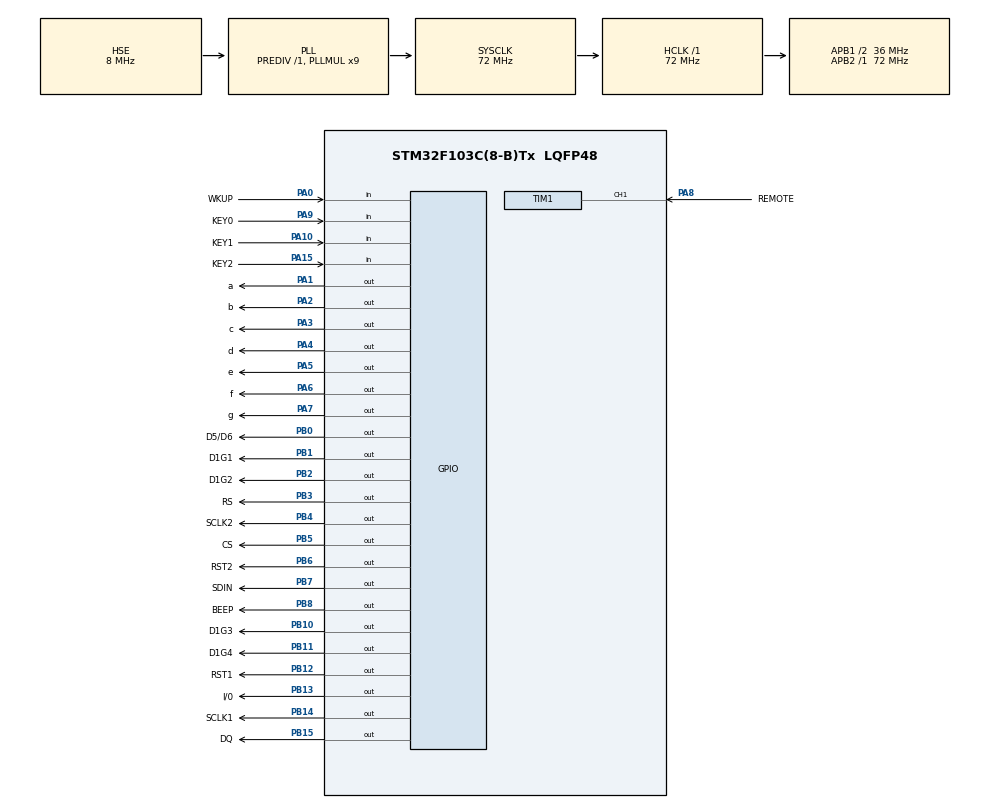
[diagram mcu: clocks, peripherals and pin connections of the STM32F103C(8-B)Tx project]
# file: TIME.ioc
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Mcu.Family=STM32F1
Mcu.Name=STM32F103C(8-B)Tx
Mcu.Package=LQFP48
NVIC.PriorityGroup=NVIC_PRIORITYGROUP_2
NVIC.TIM1_CC_IRQn=true\:1\:3\:true\:false\:true
NVIC.TIM1_UP_IRQn=true\:1\:2\:true\:false\:true
NVIC.TIM3_IRQn=true\:1\:3\:true\:false\:true
PA0-WKUP.GPIO_Label=WKUP
PA0-WKUP.GPIO_PuPd=GPIO_PULLDOWN
PA0-WKUP.Signal=GPIO_Input
PA1.GPIO_Label=a
PA1.GPIO_Speed=GPIO_SPEED_FREQ_HIGH
PA1.PinState=GPIO_PIN_RESET
PA1.Signal=GPIO_Output
PA10.GPIO_Label=KEY1
PA10.GPIO_PuPd=GPIO_PULLUP
PA10.Signal=GPIO_Input
PA13.Mode=Serial_Wire
PA13.Signal=SYS_JTMS-SWDIO
PA14.Mode=Serial_Wire
PA14.Signal=SYS_JTCK-SWCLK
PA15.GPIO_Label=KEY2
PA15.GPIO_PuPd=GPIO_PULLUP
PA15.Signal=GPIO_Input
PA2.GPIO_Label=b
PA2.GPIO_Speed=GPIO_SPEED_FREQ_HIGH
PA2.PinState=GPIO_PIN_RESET
PA2.Signal=GPIO_Output
PA3.GPIO_Label=c
PA3.GPIO_Speed=GPIO_SPEED_FREQ_HIGH
PA3.Signal=GPIO_Output
PA4.GPIO_Label=d
PA4.GPIO_Speed=GPIO_SPEED_FREQ_HIGH
PA4.Signal=GPIO_Output
PA5.GPIO_Label=e
PA5.GPIO_Speed=GPIO_SPEED_FREQ_HIGH
PA5.Signal=GPIO_Output
PA6.GPIO_Label=f
PA6.GPIO_Speed=GPIO_SPEED_FREQ_HIGH
PA6.Signal=GPIO_Output
PA7.GPIO_Label=g
PA7.GPIO_Speed=GPIO_SPEED_FREQ_HIGH
PA7.Signal=GPIO_Output
PA8.GPIO_Label=REMOTE
PA8.GPIO_PuPd=GPIO_PULLUP
PA8.Signal=S_TIM1_CH1
PA9.GPIO_Label=KEY0
PA9.GPIO_PuPd=GPIO_PULLUP
PA9.Signal=GPIO_Input
PB0.GPIO_Label=D5/D6
PB0.GPIO_Speed=GPIO_SPEED_FREQ_HIGH
PB0.Signal=GPIO_Output
PB1.GPIO_Label=D1G1
PB1.GPIO_Speed=GPIO_SPEED_FREQ_HIGH
PB1.Signal=GPIO_Output
PB10.GPIO_Label=D1G3
PB10.GPIO_Speed=GPIO_SPEED_FREQ_HIGH
PB10.Signal=GPIO_Output
PB11.GPIO_Label=D1G4
PB11.GPIO_Speed=GPIO_SPEED_FREQ_HIGH
PB11.Signal=GPIO_Output
PB12.GPIO_Label=RST1
PB12.GPIO_Speed=GPIO_SPEED_FREQ_HIGH
PB12.Signal=GPIO_Output
PB13.GPIO_Label=I/0
PB13.GPIO_Speed=GPIO_SPEED_FREQ_HIGH
PB13.Signal=GPIO_Output
PB14.GPIO_Label=SCLK1
PB14.GPIO_Speed=GPIO_SPEED_FREQ_HIGH
PB14.Signal=GPIO_Output
PB15.GPIO_Label=DQ
PB15.GPIO_Speed=GPIO_SPEED_FREQ_HIGH
PB15.Signal=GPIO_Output
PB2.GPIO_Label=D1G2
PB2.GPIO_Speed=GPIO_SPEED_FREQ_HIGH
PB2.Signal=GPIO_Output
PB3.GPIO_Label=RS
PB3.GPIO_Speed=GPIO_SPEED_FREQ_HIGH
PB3.Signal=GPIO_Output
PB4.GPIO_Label=SCLK2
PB4.GPIO_Speed=GPIO_SPEED_FREQ_HIGH
PB4.Signal=GPIO_Output
PB5.GPIO_Label=CS
PB5.GPIO_Speed=GPIO_SPEED_FREQ_HIGH
PB5.Signal=GPIO_Output
PB6.GPIO_Label=RST2
PB6.GPIO_Speed=GPIO_SPEED_FREQ_HIGH
PB6.Signal=GPIO_Output
PB7.GPIO_Label=SDIN
PB7.GPIO_Speed=GPIO_SPEED_FREQ_HIGH
PB7.Signal=GPIO_Output
PB8.GPIO_Label=BEEP
PB8.GPIO_Speed=GPIO_SPEED_FREQ_HIGH
PB8.PinState=GPIO_PIN_RESET
PB8.Signal=GPIO_Output
PD0-OSC_IN.Mode=HSE-External-Oscillator
PD0-OSC_IN.Signal=RCC_OSC_IN
PD1-OSC_OUT.Mode=HSE-External-Oscillator
PD1-OSC_OUT.Signal=RCC_OSC_OUT
ProjectManager.HeapSize=0x200
ProjectManager.StackSize=0x400
ProjectManager.TargetToolchain=MDK-ARM V5
RCC.AHBFreq_Value=72000000
RCC.APB1CLKDivider=RCC_HCLK_DIV2
RCC.APB1Freq_Value=36000000
RCC.APB1TimFreq_Value=72000000
RCC.APB2Freq_Value=72000000
RCC.APB2TimFreq_Value=72000000
RCC.HCLKFreq_Value=72000000
RCC.PLLMUL=RCC_PLL_MUL9
RCC.PLLSourceVirtual=RCC_PLLSOURCE_HSE
RCC.SYSCLKFreq_VALUE=72000000
RCC.SYSCLKSource=RCC_SYSCLKSOURCE_PLLCLK
RCC.USBFreq_Value=72000000
SH.S_TIM1_CH1.0=TIM1_CH1,Input_Capture1_from_TI1
TIM1.Channel-Input_Capture1_from_TI1=TIM_CHANNEL_1
TIM1.ICFilter_CH1=0x03
TIM1.Period=10000
TIM1.Prescaler=71
TIM3.Period=999
TIM3.Prescaler=71
VP_TIM1_VS_ClockSourceINT.Mode=Internal
VP_TIM3_VS_ClockSourceINT.Mode=Internal
board=TIME

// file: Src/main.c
/**
  ******************************************************************************
  * File Name          : main.c
  * Description        : Main program body
  ******************************************************************************
  ** This notice applies to any and all portions of this file
  * that are not between comment pairs USER CODE BEGIN and
  * USER CODE END. Other portions of this file, whether
  * inserted by the user or by software development tools
  * are owned by their respective copyright owners.
  *
  * COPYRIGHT(c) 2017 STMicroelectronics
  *
  * Redistribution and use in source and binary forms, with or without modification,
  * are permitted provided that the following conditions are met:
  *   1. Redistributions of source code must retain the above copyright notice,
  *      this list of conditions and the following disclaimer.
  *   2. Redistributions in binary form must reproduce the above copyright notice,
  *      this list of conditions and the following disclaimer in the documentation
  *      and/or other materials provided with the distribution.
  *   3. Neither the name of STMicroelectronics nor the names of its contributors
  *      may be used to endorse or promote products derived from this software
  *      without specific prior written permission.
  *
  * THIS SOFTWARE IS PROVIDED BY THE COPYRIGHT HOLDERS AND CONTRIBUTORS "AS IS"
  * AND ANY EXPRESS OR IMPLIED WARRANTIES, INCLUDING, BUT NOT LIMITED TO, THE
  * IMPLIED WARRANTIES OF MERCHANTABILITY AND FITNESS FOR A PARTICULAR PURPOSE ARE
  * DISCLAIMED. IN NO EVENT SHALL THE COPYRIGHT HOLDER OR CONTRIBUTORS BE LIABLE
  * FOR ANY DIRECT, INDIRECT, INCIDENTAL, SPECIAL, EXEMPLARY, OR CONSEQUENTIAL
  * DAMAGES (INCLUDING, BUT NOT LIMITED TO, PROCUREMENT OF SUBSTITUTE GOODS OR
  * SERVICES; LOSS OF USE, DATA, OR PROFITS; OR BUSINESS INTERRUPTION) HOWEVER
  * CAUSED AND ON ANY THEORY OF LIABILITY, WHETHER IN CONTRACT, STRICT LIABILITY,
  * OR TORT (INCLUDING NEGLIGENCE OR OTHERWISE) ARISING IN ANY WAY OUT OF THE USE
  * OF THIS SOFTWARE, EVEN IF ADVISED OF THE POSSIBILITY OF SUCH DAMAGE.
  *
  ******************************************************************************
  */
#include "main.h"
#include "stm32f1xx_hal.h"

/* USER CODE BEGIN Includes */
#include "oled.h"
#include "clock.h"
#include "ds1302.h"
#include "ds18b20.h"

/* USER CODE END Includes */

TIM_HandleTypeDef htim1;
TIM_HandleTypeDef htim3;

/* USER CODE BEGIN PV */
/* Private variables ---------------------------------------------------------*/

/* USER CODE END PV */

void SystemClock_Config(void);
static void MX_GPIO_Init(void);
static void MX_TIM1_Init(void);
static void MX_TIM3_Init(void);

/* USER CODE BEGIN PFP */
/* Private function prototypes -----------------------------------------------*/

/* USER CODE END PFP */

int main(void)
{

  /* MCU Configuration----------------------------------------------------------*/

  /* Reset of all peripherals, Initializes the Flash interface and the Systick. */
  HAL_Init();

  /* Configure the system clock */
  SystemClock_Config();

  /* Initialize all configured peripherals */
  MX_GPIO_Init();
  MX_TIM1_Init();
  MX_TIM3_Init();

  /* USER CODE BEGIN 2 */
	OLED_Init();
	OLED_Clear();
	DS1302_Init();
	DS18B20_Init();
  HAL_TIM_Base_Start_IT(&htim3);
	HAL_TIM_Base_Start_IT(&htim1);
	HAL_TIM_IC_Start_IT(&htim1,TIM_CHANNEL_1);
  /* USER CODE END 2 */

  /* Infinite loop */
  while (1)
  {

  /* USER CODE BEGIN 3 */
    clock();
  }
  /* USER CODE END 3 */

}

/** System Clock Configuration
*/
void SystemClock_Config(void)
{

  RCC_OscInitTypeDef RCC_OscInitStruct;
  RCC_ClkInitTypeDef RCC_ClkInitStruct;

    /**Initializes the CPU, AHB and APB busses clocks
    */
  RCC_OscInitStruct.OscillatorType = RCC_OSCILLATORTYPE_HSE;
  RCC_OscInitStruct.HSEState = RCC_HSE_ON;
  RCC_OscInitStruct.HSEPredivValue = RCC_HSE_PREDIV_DIV1;
  RCC_OscInitStruct.HSIState = RCC_HSI_ON;
  RCC_OscInitStruct.PLL.PLLState = RCC_PLL_ON;
  RCC_OscInitStruct.PLL.PLLSource = RCC_PLLSOURCE_HSE;
  RCC_OscInitStruct.PLL.PLLMUL = RCC_PLL_MUL9;
  if (HAL_RCC_OscConfig(&RCC_OscInitStruct) != HAL_OK)
  {
    _Error_Handler(__FILE__, __LINE__);
  }

    /**Initializes the CPU, AHB and APB busses clocks
    */
  RCC_ClkInitStruct.ClockType = RCC_CLOCKTYPE_HCLK|RCC_CLOCKTYPE_SYSCLK
                              |RCC_CLOCKTYPE_PCLK1|RCC_CLOCKTYPE_PCLK2;
  RCC_ClkInitStruct.SYSCLKSource = RCC_SYSCLKSOURCE_PLLCLK;
  RCC_ClkInitStruct.AHBCLKDivider = RCC_SYSCLK_DIV1;
  RCC_ClkInitStruct.APB1CLKDivider = RCC_HCLK_DIV2;
  RCC_ClkInitStruct.APB2CLKDivider = RCC_HCLK_DIV1;

  if (HAL_RCC_ClockConfig(&RCC_ClkInitStruct, FLASH_LATENCY_2) != HAL_OK)
  {
    _Error_Handler(__FILE__, __LINE__);
  }

    /**Configure the Systick interrupt time
    */
  HAL_SYSTICK_Config(HAL_RCC_GetHCLKFreq()/1000);

    /**Configure the Systick
    */
  HAL_SYSTICK_CLKSourceConfig(SYSTICK_CLKSOURCE_HCLK);

  /* SysTick_IRQn interrupt configuration */
  HAL_NVIC_SetPriority(SysTick_IRQn, 0, 0);
}

/* TIM1 init function */
static void MX_TIM1_Init(void)
{

  TIM_ClockConfigTypeDef sClockSourceConfig;
  TIM_MasterConfigTypeDef sMasterConfig;
  TIM_IC_InitTypeDef sConfigIC;

  htim1.Instance = TIM1;
  htim1.Init.Prescaler = 71;
  htim1.Init.CounterMode = TIM_COUNTERMODE_UP;
  htim1.Init.Period = 10000;
  htim1.Init.ClockDivision = TIM_CLOCKDIVISION_DIV1;
  htim1.Init.RepetitionCounter = 0;
  htim1.Init.AutoReloadPreload = TIM_AUTORELOAD_PRELOAD_DISABLE;
  if (HAL_TIM_Base_Init(&htim1) != HAL_OK)
  {
    _Error_Handler(__FILE__, __LINE__);
  }

  sClockSourceConfig.ClockSource = TIM_CLOCKSOURCE_INTERNAL;
  if (HAL_TIM_ConfigClockSource(&htim1, &sClockSourceConfig) != HAL_OK)
  {
    _Error_Handler(__FILE__, __LINE__);
  }

  if (HAL_TIM_IC_Init(&htim1) != HAL_OK)
  {
    _Error_Handler(__FILE__, __LINE__);
  }

  sMasterConfig.MasterOutputTrigger = TIM_TRGO_RESET;
  sMasterConfig.MasterSlaveMode = TIM_MASTERSLAVEMODE_DISABLE;
  if (HAL_TIMEx_MasterConfigSynchronization(&htim1, &sMasterConfig) != HAL_OK)
  {
    _Error_Handler(__FILE__, __LINE__);
  }

  sConfigIC.ICPolarity = TIM_INPUTCHANNELPOLARITY_RISING;
  sConfigIC.ICSelection = TIM_ICSELECTION_DIRECTTI;
  sConfigIC.ICPrescaler = TIM_ICPSC_DIV1;
  sConfigIC.ICFilter = 0x03;
  if (HAL_TIM_IC_ConfigChannel(&htim1, &sConfigIC, TIM_CHANNEL_1) != HAL_OK)
  {
    _Error_Handler(__FILE__, __LINE__);
  }

}

/* TIM3 init function */
static void MX_TIM3_Init(void)
{

  TIM_ClockConfigTypeDef sClockSourceConfig;
  TIM_MasterConfigTypeDef sMasterConfig;

  htim3.Instance = TIM3;
  htim3.Init.Prescaler = 71;
  htim3.Init.CounterMode = TIM_COUNTERMODE_UP;
  htim3.Init.Period = 999;
  htim3.Init.ClockDivision = TIM_CLOCKDIVISION_DIV1;
  htim3.Init.AutoReloadPreload = TIM_AUTORELOAD_PRELOAD_DISABLE;
  if (HAL_TIM_Base_Init(&htim3) != HAL_OK)
  {
    _Error_Handler(__FILE__, __LINE__);
  }

  sClockSourceConfig.ClockSource = TIM_CLOCKSOURCE_INTERNAL;
  if (HAL_TIM_ConfigClockSource(&htim3, &sClockSourceConfig) != HAL_OK)
  {
    _Error_Handler(__FILE__, __LINE__);
  }

  sMasterConfig.MasterOutputTrigger = TIM_TRGO_RESET;
  sMasterConfig.MasterSlaveMode = TIM_MASTERSLAVEMODE_DISABLE;
  if (HAL_TIMEx_MasterConfigSynchronization(&htim3, &sMasterConfig) != HAL_OK)
  {
    _Error_Handler(__FILE__, __LINE__);
  }

}

/** Configure pins as
        * Analog
        * Input
        * Output
        * EVENT_OUT
        * EXTI
*/
static void MX_GPIO_Init(void)
{

  GPIO_InitTypeDef GPIO_InitStruct;

  /* GPIO Ports Clock Enable */
  __HAL_RCC_GPIOD_CLK_ENABLE();
  __HAL_RCC_GPIOA_CLK_ENABLE();
  __HAL_RCC_GPIOB_CLK_ENABLE();

  /*Configure GPIO pin Output Level */
  HAL_GPIO_WritePin(GPIOA, a_Pin|b_Pin|c_Pin|d_Pin
                          |e_Pin|f_Pin|g_Pin, GPIO_PIN_RESET);

  /*Configure GPIO pin Output Level */
  HAL_GPIO_WritePin(GPIOB, D5_D6_Pin|D1G1_Pin|D1G2_Pin|D1G3_Pin
                          |D1G4_Pin|RST1_Pin|I_0_Pin|SCLK1_Pin
                          |DQ_Pin|RS_Pin|SCLK2_Pin|CS_Pin
                          |RST2_Pin|SDIN_Pin|BEEP_Pin, GPIO_PIN_RESET);

  /*Configure GPIO pin : WKUP_Pin */
  GPIO_InitStruct.Pin = WKUP_Pin;
  GPIO_InitStruct.Mode = GPIO_MODE_INPUT;
  GPIO_InitStruct.Pull = GPIO_PULLDOWN;
  HAL_GPIO_Init(WKUP_GPIO_Port, &GPIO_InitStruct);

  /*Configure GPIO pins : a_Pin b_Pin c_Pin d_Pin
                           e_Pin f_Pin g_Pin */
  GPIO_InitStruct.Pin = a_Pin|b_Pin|c_Pin|d_Pin
                          |e_Pin|f_Pin|g_Pin;
  GPIO_InitStruct.Mode = GPIO_MODE_OUTPUT_PP;
  GPIO_InitStruct.Speed = GPIO_SPEED_FREQ_HIGH;
  HAL_GPIO_Init(GPIOA, &GPIO_InitStruct);

  /*Configure GPIO pins : D5_D6_Pin D1G1_Pin D1G2_Pin D1G3_Pin
                           D1G4_Pin RST1_Pin I_0_Pin SCLK1_Pin
                           DQ_Pin RS_Pin SCLK2_Pin CS_Pin
                           RST2_Pin SDIN_Pin BEEP_Pin */
  GPIO_InitStruct.Pin = D5_D6_Pin|D1G1_Pin|D1G2_Pin|D1G3_Pin
                          |D1G4_Pin|RST1_Pin|I_0_Pin|SCLK1_Pin
                          |DQ_Pin|RS_Pin|SCLK2_Pin|CS_Pin
                          |RST2_Pin|SDIN_Pin|BEEP_Pin;
  GPIO_InitStruct.Mode = GPIO_MODE_OUTPUT_PP;
  GPIO_InitStruct.Speed = GPIO_SPEED_FREQ_HIGH;
  HAL_GPIO_Init(GPIOB, &GPIO_InitStruct);

  /*Configure GPIO pins : KEY0_Pin KEY1_Pin KEY2_Pin */
  GPIO_InitStruct.Pin = KEY0_Pin|KEY1_Pin|KEY2_Pin;
  GPIO_InitStruct.Mode = GPIO_MODE_INPUT;
  GPIO_InitStruct.Pull = GPIO_PULLUP;
  HAL_GPIO_Init(GPIOA, &GPIO_InitStruct);

}

void _Error_Handler(char * file, int line)
{
  while(1)
  {
  }
}

/************************ (C) COPYRIGHT STMicroelectronics *****END OF FILE****/
